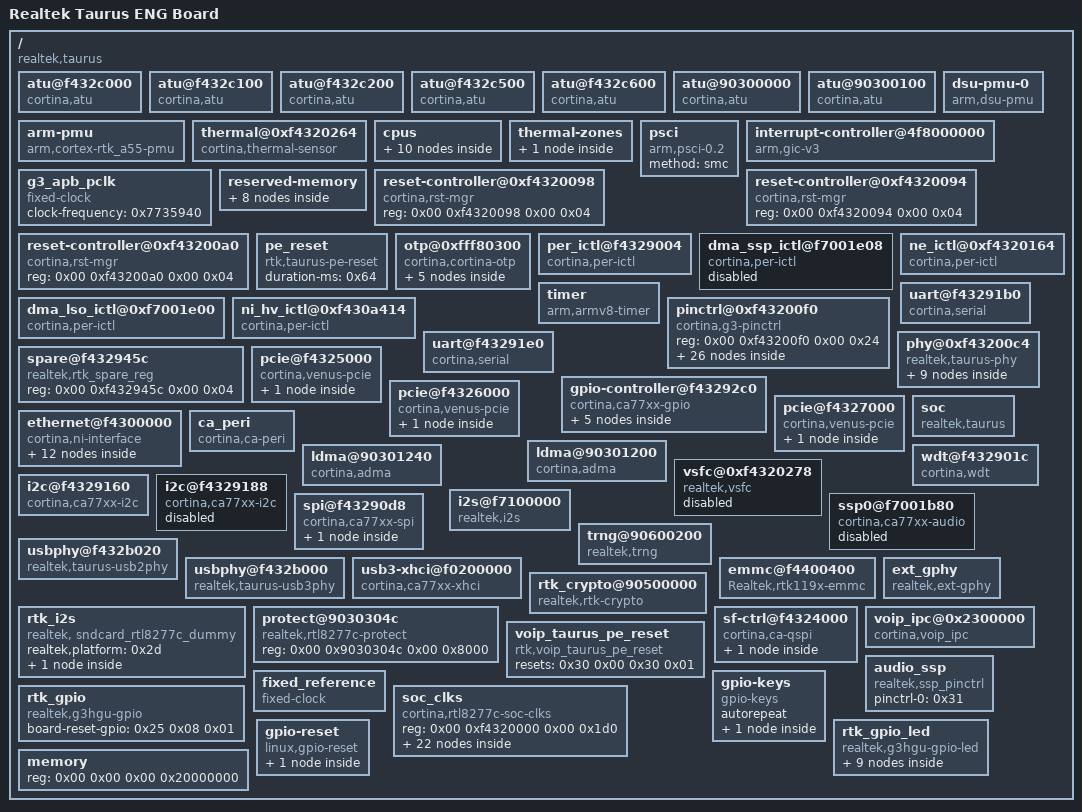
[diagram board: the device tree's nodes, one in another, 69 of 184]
/dts-v1/;

/ {
	model = "Realtek Taurus ENG Board";
	compatible = "realtek,taurus";
	#address-cells = <0x02>;
	#size-cells = <0x02>;
	interrupt-parent = <0x01>;

	atu@f432c000 {
		compatible = "cortina,atu";
		reg = <0x00 0xf432c000 0x00 0x1c>;
		reg-names = "pcie0_atu";
		atu-type = <0x00>;
		coherent-hi-addr = <0x04>;
		#iommu-cells = <0x00>;
		phandle = <0x0f>;
	};

	atu@f432c100 {
		compatible = "cortina,atu";
		reg = <0x00 0xf432c100 0x00 0x1c>;
		reg-names = "pcie1_atu";
		atu-type = <0x00>;
		coherent-hi-addr = <0x04>;
		#iommu-cells = <0x00>;
		phandle = <0x14>;
	};

	atu@f432c200 {
		compatible = "cortina,atu";
		reg = <0x00 0xf432c200 0x00 0x1c>;
		reg-names = "pcie2_atu";
		atu-type = <0x00>;
		coherent-hi-addr = <0x04>;
		#iommu-cells = <0x00>;
		phandle = <0x18>;
	};

	atu@f432c500 {
		compatible = "cortina,atu";
		reg = <0x00 0xf432c500 0x00 0x1c>;
		reg-names = "usb0_atu";
		atu-type = <0x00>;
		coherent-hi-addr = <0x02>;
		#iommu-cells = <0x00>;
	};

	atu@f432c600 {
		compatible = "cortina,atu";
		reg = <0x00 0xf432c600 0x00 0x1c>;
		reg-names = "usb1_atu";
		atu-type = <0x00>;
		coherent-hi-addr = <0x02>;
		#iommu-cells = <0x00>;
	};

	atu@90300000 {
		compatible = "cortina,atu";
		reg = <0x00 0x90300000 0x00 0x20>;
		reg-names = "pe0_atu";
		atu-type = <0x01>;
		#iommu-cells = <0x00>;
		keep-init;
	};

	atu@90300100 {
		compatible = "cortina,atu";
		reg = <0x00 0x90300100 0x00 0x20>;
		reg-names = "pe1_atu";
		atu-type = <0x01>;
		#iommu-cells = <0x00>;
		keep-init;
	};

	arm-pmu {
		compatible = "arm,cortex-rtk_a55-pmu";
		interrupt-parent = <0x01>;
		interrupts = <0x01 0x17 0x04>;
	};

	dsu-pmu-0 {
		compatible = "arm,dsu-pmu";
		interrupt-parent = <0x01>;
		interrupts = <0x00 0x6a 0x04>;
		cpus = <0x02 0x03 0x04 0x05>;
	};

	thermal@0xf4320264 {
		compatible = "cortina,thermal-sensor";
		reg = <0x00 0xf4320264 0x00 0x10>;
		status = "okay";
		tms-reg-a = <0x7f80000>;
		tms-reg-b = <0x374000>;
		#thermal-sensor-cells = <0x00>;
		phandle = <0x07>;
	};

	cpus {
		#address-cells = <0x02>;
		#size-cells = <0x00>;

		cpu@0 {
			compatible = "arm,cortex-a55\0arm,armv8";
			device_type = "cpu";
			reg = <0x00 0x00>;
			clocks = <0x06>;
			clock-names = "cpu";
			operating-points = <0x124f80 0xf4240 0x10c8e0 0xf4240 0xf4240 0xf4240 0xdbba0 0xf4240 0xc3500 0xf4240 0xaae60 0xf4240 0x98968 0xf4240 0x61a80 0xf4240>;
			enable-method = "psci";
			#cooling-cells = <0x02>;
			phandle = <0x02>;
		};

		cpu@100 {
			compatible = "arm,cortex-a55\0arm,armv8";
			device_type = "cpu";
			reg = <0x00 0x100>;
			clocks = <0x06>;
			clock-names = "cpu";
			operating-points = <0x124f80 0xf4240 0x10c8e0 0xf4240 0xf4240 0xf4240 0xdbba0 0xf4240 0xc3500 0xf4240 0xaae60 0xf4240 0x98968 0xf4240 0x61a80 0xf4240>;
			enable-method = "psci";
			#cooling-cells = <0x02>;
			phandle = <0x03>;
		};

		cpu@200 {
			compatible = "arm,cortex-a55\0arm,armv8";
			device_type = "cpu";
			reg = <0x00 0x200>;
			clocks = <0x06>;
			clock-names = "cpu";
			operating-points = <0x124f80 0xf4240 0x10c8e0 0xf4240 0xf4240 0xf4240 0xdbba0 0xf4240 0xc3500 0xf4240 0xaae60 0xf4240 0x98968 0xf4240 0x61a80 0xf4240>;
			enable-method = "psci";
			#cooling-cells = <0x02>;
			phandle = <0x04>;
		};

		cpu@300 {
			compatible = "arm,cortex-a55\0arm,armv8";
			device_type = "cpu";
			reg = <0x00 0x300>;
			clocks = <0x06>;
			clock-names = "cpu";
			operating-points = <0x124f80 0xf4240 0x10c8e0 0xf4240 0xf4240 0xf4240 0xdbba0 0xf4240 0xc3500 0xf4240 0xaae60 0xf4240 0x98968 0xf4240 0x61a80 0xf4240>;
			enable-method = "psci";
			#cooling-cells = <0x02>;
			phandle = <0x05>;
		};

		cpu-map {

			cluster0 {

				core0 {
					cpu = <0x02>;
				};

				core1 {
					cpu = <0x03>;
				};

				core2 {
					cpu = <0x04>;
				};

				core3 {
					cpu = <0x05>;
				};
			};
		};
	};

	thermal-zones {

		cpu-thermal {
			polling-delay-passive = <0x1f4>;
			polling-delay = <0xbb8>;
			thermal-sensors = <0x07>;
		};
	};

	psci {
		compatible = "arm,psci-0.2";
		method = "smc";
	};

	interrupt-controller@4f8000000 {
		compatible = "arm,gic-v3";
		#interrupt-cells = <0x03>;
		interrupt-controller;
		#redistributor-regions = <0x01>;
		reg = <0x04 0xf8000000 0x00 0x10000 0x04 0xf8040000 0x00 0x80000>;
		interrupts = <0x01 0x09 0x04>;
		phandle = <0x01>;
	};

	g3_apb_pclk {
		compatible = "fixed-clock";
		#clock-cells = <0x00>;
		clock-frequency = <0x7735940>;
		phandle = <0x09>;
	};

	reserved-memory {
		#address-cells = <0x02>;
		#size-cells = <0x02>;
		ranges;

		ddr_cache_buffer@0x0bc48000 {
			reg = <0x00 0xbc48000 0x00 0x60000>;
			phandle = <0x21>;
		};

		ddr_noncache_buffer@0x09000000 {
			reg = <0x00 0x9000000 0x00 0x1a50000>;
			phandle = <0x22>;
		};

		tz_buffer@FFE0000 {
			reg = <0x00 0xffe0000 0x00 0x20000>;
		};

		tz_smc_buf@0xFFDF000 {
			reg = <0x00 0xffdf000 0x00 0x1000>;
			no-map;
		};

		pstore_buf@0xEF00000 {
			no-map;
			reg = <0x00 0xef00000 0x00 0x100000>;
		};

		voip_vector_buffer@0x0 {
			reg = <0x00 0x00 0x00 0x1000>;
			no-map;
		};

		voip_buffer@0x2000000 {
			reg = <0x00 0x2000000 0x00 0x300000>;
			no-map;
			phandle = <0x2f>;
		};

		voip_ipc_noncache_buffer@0x2300000 {
			reg = <0x00 0x2300000 0x00 0x100000>;
			no-map;
			phandle = <0x2e>;
		};
	};

	reset-controller@0xf4320098 {
		compatible = "cortina,rst-mgr";
		reg = <0x00 0xf4320098 0x00 0x04>;
		#reset-cells = <0x01>;
		phandle = <0x1e>;
	};

	reset-controller@0xf4320094 {
		compatible = "cortina,rst-mgr";
		reg = <0x00 0xf4320094 0x00 0x04>;
		#reset-cells = <0x01>;
		phandle = <0x20>;
	};

	reset-controller@0xf43200a0 {
		compatible = "cortina,rst-mgr";
		reg = <0x00 0xf43200a0 0x00 0x04>;
		#reset-cells = <0x01>;
		phandle = <0x1f>;
	};

	pe_reset {
		compatible = "rtk,taurus-pe-reset";
		duration-ms = <0x64>;
		#reset-cells = <0x01>;
		phandle = <0x30>;
	};

	otp@0xfff80300 {
		compatible = "cortina,cortina-otp";
		#address-cells = <0x01>;
		#size-cells = <0x01>;
		reg = <0x00 0xfff80300 0x00 0x100>;
		ngroups = <0x100>;
		redundant;

		uuid@0x74 {
			reg = <0x74 0x04>;
		};

		hvsid@0x78 {
			reg = <0x78 0x04>;
		};

		param@0x80 {
			reg = <0x80 0x04>;
			phandle = <0x1b>;
		};

		patch@0x84 {
			reg = <0x84 0x10>;
			phandle = <0x1d>;
		};

		calib@0x94 {
			reg = <0x94 0x20>;
			phandle = <0x1c>;
		};
	};

	per_ictl@f4329004 {
		compatible = "cortina,per-ictl";
		reg = <0x00 0xf4329004 0x00 0x10>;
		interrupt-controller;
		#interrupt-cells = <0x01>;
		interrupt-parent = <0x01>;
		interrupts = <0x00 0x02 0x04>;
		phandle = <0x0a>;
	};

	dma_ssp_ictl@f7001e08 {
		compatible = "cortina,per-ictl";
		reg = <0x00 0xf7001e08 0x00 0x08>;
		interrupt-controller;
		#interrupt-cells = <0x01>;
		interrupt-parent = <0x01>;
		interrupts = <0x00 0x10 0x04>;
		status = "disabled";
		phandle = <0x28>;
	};

	dma_lso_ictl@0xf7001e00 {
		compatible = "cortina,per-ictl";
		reg = <0x00 0xf7001e00 0x00 0x08>;
		interrupt-controller;
		#interrupt-cells = <0x01>;
		interrupt-parent = <0x01>;
		interrupts = <0x00 0x08 0x04>;
		phandle = <0x23>;
	};

	ne_ictl@0xf4320164 {
		compatible = "cortina,per-ictl";
		reg = <0x00 0xf4320164 0x00 0x10>;
		interrupt-controller;
		#interrupt-cells = <0x01>;
		interrupt-parent = <0x01>;
		interrupts = <0x00 0x01 0x04>;
		phandle = <0x08>;
	};

	ni_hv_ictl@0xf430a414 {
		compatible = "cortina,per-ictl";
		reg = <0x00 0xf430a414 0x00 0x08>;
		interrupt-controller;
		#interrupt-cells = <0x01>;
		interrupt-parent = <0x08>;
		interrupts = <0x00>;
		phandle = <0x24>;
	};

	timer {
		compatible = "arm,armv8-timer";
		interrupt-parent = <0x01>;
		interrupts = <0x01 0x0d 0xff08 0x01 0x0e 0xff08 0x01 0x0b 0xff08 0x01 0x0a 0xff08>;
		clock-frequency = <0x17d7840>;
	};

	pinctrl@0xf43200f0 {
		compatible = "cortina,g3-pinctrl";
		reg = <0x00 0xf43200f0 0x00 0x24>;
		phandle = <0x0b>;

		uart0_active {

			data_signals {
				pins = "PMUX_003";
				function = "multi-fn";
			};
		};

		uart2_active {

			data_signals {
				pins = "GPIO_000\0GPIO_001\0PMUX_004";
				function = "multi-fn";
			};
		};

		uart3_active {

			data_signals {
				pins = "GPIO_002\0GPIO_003\0PMUX_005";
				function = "multi-fn";
			};
		};

		spi_cs1 {

			data_signals {
				pins = "GPIO_004\0PMUX_006";
				function = "multi-fn";
			};
		};

		spi_cs2 {

			data_signals {
				pins = "GPIO_005\0PMUX_007";
				function = "multi-fn";
			};
		};

		spi_cs3 {

			data_signals {
				pins = "GPIO_006\0PMUX_008";
				function = "multi-fn";
			};
		};

		spi_cs4 {

			data_signals {
				pins = "GPIO_007\0PMUX_009";
				function = "multi-fn";
			};
		};

		led_ctrl_active {

			data_signals {
				pins = "GPIO_011\0GPIO_012\0PMUX_019";
				function = "multi-fn";
			};
		};

		mdio_default {

			data_signals {
				pins = "GPIO_402\0GPIO_403\0PMUX_111";
				function = "multi-fn";
			};
		};

		i2c0_default {
			phandle = <0x26>;

			data_signals {
				pins = "GPIO_204\0GPIO_205\0PMUX_120";
				function = "multi-fn";
			};
		};

		rgmii_default {

			data_signals {
				pins = "GPIO_313\0GPIO_314\0GPIO_315\0GPIO_316\0GPIO_317\0GPIO_318\0GPIO_319\0GPIO_320\0GPIO_321\0GPIO_322\0GPIO_323\0GPIO_324\0PMUX_114";
				function = "multi-fn";
			};
		};

		voip_spi {
			phandle = <0x27>;

			data_signals {
				pins = "GPIO_200\0GPIO_201\0GPIO_202\0GPIO_203\0PMUX_106";
				function = "multi-fn";
			};
		};

		ssp {
			phandle = <0x31>;

			data_signals {
				pins = "GPIO_206\0GPIO_207\0GPIO_208\0GPIO_209\0GPIO_210\0GPIO_211\0PMUX_104";
				function = "multi-fn";
			};
		};
	};

	uart@f43291b0 {
		device_type = "serial";
		compatible = "cortina,serial";
		reg = <0x00 0xf43291b0 0x00 0x30>;
		clocks = <0x09>;
		interrupts = <0x00 0x04 0x04>;
		wakeup-source;
	};

	uart@f43291e0 {
		device_type = "serial";
		compatible = "cortina,serial";
		reg = <0x00 0xf43291e0 0x00 0x30>;
		clocks = <0x09>;
		interrupts = <0x00 0x05 0x04>;
	};

	spare@f432945c {
		compatible = "realtek,rtk_spare_reg";
		reg = <0x00 0xf432945c 0x00 0x04>;
	};

	gpio-controller@f43292c0 {
		#address-cells = <0x01>;
		#size-cells = <0x00>;
		compatible = "cortina,ca77xx-gpio";
		reg = <0x00 0xf43292c0 0x00 0xb4 0x00 0xf4320100 0x00 0x14>;
		id = <0x00>;

		bank@0 {
			gpio-controller;
			interrupt-controller;
			reg = <0x00>;
			ngpios = <0x10>;
			#gpio-cells = <0x02>;
			#interrupt-cells = <0x02>;
			interrupt-parent = <0x0a>;
			interrupts = <0x08>;
			gpio-ranges = <0x0b 0x00 0x00 0x20>;
			phandle = <0x25>;
		};

		bank@1 {
			gpio-controller;
			interrupt-controller;
			reg = <0x01>;
			ngpios = <0x11>;
			#gpio-cells = <0x02>;
			#interrupt-cells = <0x02>;
			interrupt-parent = <0x0a>;
			interrupts = <0x09>;
			gpio-ranges = <0x0b 0x00 0x20 0x20>;
		};

		bank@2 {
			gpio-controller;
			interrupt-controller;
			reg = <0x02>;
			ngpios = <0x0c>;
			#gpio-cells = <0x02>;
			#interrupt-cells = <0x02>;
			interrupt-parent = <0x0a>;
			interrupts = <0x0a>;
			gpio-ranges = <0x0b 0x00 0x40 0x20>;
		};

		bank@3 {
			gpio-controller;
			interrupt-controller;
			reg = <0x03>;
			ngpios = <0x19>;
			#gpio-cells = <0x02>;
			#interrupt-cells = <0x02>;
			interrupt-parent = <0x0a>;
			interrupts = <0x0b>;
			gpio-ranges = <0x0b 0x00 0x60 0x20>;
		};

		bank@4 {
			gpio-controller;
			interrupt-controller;
			reg = <0x04>;
			ngpios = <0x11>;
			#gpio-cells = <0x02>;
			#interrupt-cells = <0x02>;
			interrupt-parent = <0x0a>;
			interrupts = <0x0c>;
			gpio-ranges = <0x0b 0x00 0x80 0x20>;
			phandle = <0x3d>;
		};
	};

	phy@0xf43200c4 {
		#address-cells = <0x01>;
		#size-cells = <0x00>;
		compatible = "realtek,taurus-phy";
		reg = <0x00 0xf43200c4 0x00 0x20 0x00 0xf432036c 0x00 0x04>;
		reg-names = "control\0power";

		phy@0 {
			reg = <0x00>;
			#phy-cells = <0x00>;
			phandle = <0x0c>;
		};

		phy@1 {
			reg = <0x01>;
			#phy-cells = <0x00>;
			phandle = <0x0d>;
		};

		phy@9 {
			reg = <0x09>;
			#phy-cells = <0x00>;
		};

		phy@2 {
			reg = <0x02>;
			#phy-cells = <0x00>;
			phandle = <0x11>;
		};

		phy@3 {
			reg = <0x03>;
			#phy-cells = <0x00>;
			phandle = <0x12>;
		};

		phy@4 {
			reg = <0x04>;
			#phy-cells = <0x00>;
			phandle = <0x16>;
		};

		phy@5 {
			reg = <0x05>;
			#phy-cells = <0x00>;
			phandle = <0x29>;
		};

		phy@6 {
			reg = <0x06>;
			#phy-cells = <0x00>;
			phandle = <0x2a>;
		};

		phy@7 {
			reg = <0x07>;
			#phy-cells = <0x00>;
			serdes-reg = <0x00 0xf4600000 0x00 0x1000>;
			phandle = <0x1a>;
		};
	};

	pcie@f4325000 {
		compatible = "cortina,venus-pcie";
		reg = <0x00 0xf4325000 0x00 0x400 0x00 0xa0000000 0x00 0x1000 0x00 0xa0001000 0x00 0x2000 0x00 0xa0300000 0x00 0x100000 0x00 0xf4333000 0x00 0x2000>;
		reg-names = "glbl_regs\0rc_dbi\0config\0iatu\0serdes_phy";
		phys = <0x0c 0x0d>;
		phy-names = "pcie-phy0\0pcie-phy1";
		#address-cells = <0x03>;
		#size-cells = <0x02>;
		device_type = "pci";
		bus-range = <0x00 0xff>;
		ranges = <0x81000000 0x00 0x00 0x00 0xa0003000 0x00 0x10000 0x82000000 0x00 0xa0400000 0x00 0xa0400000 0x00 0xfc00000>;
		id = <0x00>;
		num-viewport = <0x01>;
		num-lanes = <0x01>;
		clocks = <0x0e>;
		iommus = <0x0f>;
		interrupt-parent = <0x01>;
		interrupts = <0x00 0x2a 0x04 0x00 0x2b 0x04 0x00 0x2c 0x04 0x00 0x2d 0x04>;
		irq-affinity = <0x01>;
		serdes-cfg-verA = "revA v1.3 (2022.04.22)";
		serdes-cfg-verB = "revB v1.2 (2022.04.22)";
		serdes-cfg-dataA = <0x04 0xa855 0x18 0x0a 0x20 0x3591 0x28 0x8670 0x2c 0xb90d 0x34 0xf71a 0x38 0x1000 0x74 0xda1f 0x80 0xd477 0x88 0x23 0x8c 0xb66 0x90 0x4f30 0xa0 0xf802 0xc0 0x55 0x24 0x500c 0x24 0x520c 0x104 0xa84a 0x118 0x0a 0x120 0x3591 0x128 0x8650 0x12c 0xb90d 0x134 0xf71a 0x138 0x1000 0x174 0xda1f 0x180 0xd477 0x184 0x55aa 0x188 0x23 0x18c 0xb66 0x1a0 0xf802 0x1bc 0x3900 0x1c0 0x4a 0x124 0x500c 0x124 0x520c>;
		serdes-cfg-dataB = <0x04 0xa855 0x08 0x60c6 0x18 0x1f 0x20 0x3591 0x28 0xf670 0x2c 0xa90d 0x34 0xf71a 0x38 0x1000 0x74 0xda1f 0x80 0xd477 0x88 0x23 0x8c 0xb66 0x90 0x4f30 0xa0 0xf802 0xc0 0x55 0xc8 0xf0f3 0x24 0x500c 0x24 0x520c 0x104 0xa84a 0x108 0x60c6 0x118 0x1f 0x120 0x3591 0x128 0xf670 0x12c 0xa90d 0x134 0xf71a 0x138 0x1000 0x174 0xda1f 0x180 0xd479 0x184 0x55aa 0x188 0x23 0x18c 0xb66 0x190 0x4f0c 0x1a0 0xf802 0x1bc 0x3900 0x1c0 0x4a 0x1c8 0xf0f3 0x124 0x500c 0x124 0x520c>;
		#interrupt-cells = <0x01>;
		interrupt-map-mask = <0x00 0x00 0x00 0x07>;
		interrupt-map = <0x00 0x00 0x00 0x01 0x10 0x00 0x00 0x00 0x00 0x02 0x10 0x01 0x00 0x00 0x00 0x03 0x10 0x02 0x00 0x00 0x00 0x04 0x10 0x03>;

		interrupt-controller {
			interrupt-controller;
			#address-cells = <0x00>;
			#interrupt-cells = <0x01>;
			phandle = <0x10>;
		};
	};

	pcie@f4326000 {
		compatible = "cortina,venus-pcie";
		reg = <0x00 0xf4326000 0x00 0x400 0x00 0xb0000000 0x00 0x1000 0x00 0xb0001000 0x00 0x2000 0x00 0xb0300000 0x00 0x100000 0x00 0xf4335000 0x00 0x2000>;
		reg-names = "glbl_regs\0rc_dbi\0config\0iatu\0serdes_phy";
		phys = <0x11 0x12>;
		phy-names = "pcie-phy0\0pcie-phy1";
		#address-cells = <0x03>;
		#size-cells = <0x02>;
		device_type = "pci";
		bus-range = <0x00 0xff>;
		ranges = <0x81000000 0x00 0x00 0x00 0xb0003000 0x00 0x10000 0x82000000 0x00 0xb0400000 0x00 0xb0400000 0x00 0xfc00000>;
		id = <0x01>;
		num-viewport = <0x01>;
		num-lanes = <0x01>;
		clocks = <0x13>;
		iommus = <0x14>;
		interrupt-parent = <0x01>;
		interrupts = <0x00 0x2e 0x04 0x00 0x2f 0x04 0x00 0x30 0x04 0x00 0x31 0x04>;
		irq-affinity = <0x01>;
		serdes-cfg-verA = "revA v1.3 (2022.04.22)";
		serdes-cfg-verB = "revB v1.2 (2022.04.22)";
		serdes-cfg-dataA = <0x04 0xa855 0x18 0x0a 0x20 0x3591 0x28 0x8670 0x2c 0xb90d 0x34 0xf71a 0x38 0x1000 0x74 0xda1f 0x80 0xd477 0x88 0x23 0x8c 0xb66 0x90 0x4f30 0xa0 0xf802 0xc0 0x55 0x24 0x500c 0x24 0x520c 0x104 0xa84a 0x118 0x0a 0x120 0x3591 0x128 0x8650 0x12c 0xb90d 0x134 0xf71a 0x138 0x1000 0x174 0xda1f 0x180 0xd477 0x184 0x55aa 0x188 0x23 0x18c 0xb66 0x1a0 0xf802 0x1bc 0x3900 0x1c0 0x4a 0x124 0x500c 0x124 0x520c>;
		serdes-cfg-dataB = <0x04 0xa855 0x08 0x60c6 0x18 0x1f 0x20 0x3591 0x28 0xf670 0x2c 0xa90d 0x34 0xf71a 0x38 0x1000 0x74 0xda1f 0x80 0xd477 0x88 0x23 0x8c 0xb66 0x90 0x4f30 0xa0 0xf802 0xc0 0x55 0xc8 0xf0f3 0x24 0x500c 0x24 0x520c 0x104 0xa84a 0x108 0x60c6 0x118 0x1f 0x120 0x3591 0x128 0xf670 0x12c 0xa90d 0x134 0xf71a 0x138 0x1000 0x174 0xda1f 0x180 0xd479 0x184 0x55aa 0x188 0x23 0x18c 0xb66 0x190 0x4f0c 0x1a0 0xf802 0x1bc 0x3900 0x1c0 0x4a 0x1c8 0xf0f3 0x124 0x500c 0x124 0x520c>;
		#interrupt-cells = <0x01>;
		interrupt-map-mask = <0x00 0x00 0x00 0x07>;
		interrupt-map = <0x00 0x00 0x00 0x01 0x15 0x00 0x00 0x00 0x00 0x02 0x15 0x01 0x00 0x00 0x00 0x03 0x15 0x02 0x00 0x00 0x00 0x04 0x15 0x03>;

		interrupt-controller {
			interrupt-controller;
			#address-cells = <0x00>;
			#interrupt-cells = <0x01>;
			phandle = <0x15>;
		};
	};

	pcie@f4327000 {
		compatible = "cortina,venus-pcie";
		reg = <0x00 0xf4327000 0x00 0x400 0x00 0xc0000000 0x00 0x1000 0x00 0xc0001000 0x00 0x2000 0x00 0xc0300000 0x00 0x100000 0x00 0xf4337000 0x00 0x1000>;
		reg-names = "glbl_regs\0rc_dbi\0config\0iatu\0serdes_phy";
		phys = <0x16>;
		phy-names = "pcie-phy0";
		#address-cells = <0x03>;
		#size-cells = <0x02>;
		device_type = "pci";
		bus-range = <0x00 0xff>;
		ranges = <0x81000000 0x00 0x00 0x00 0xc0003000 0x00 0x10000 0x82000000 0x00 0xc0400000 0x00 0xc0400000 0x00 0xfc00000>;
		id = <0x02>;
		num-viewport = <0x01>;
		num-lanes = <0x01>;
		clocks = <0x17>;
		iommus = <0x18>;
		interrupt-parent = <0x01>;
		interrupts = <0x00 0x32 0x04 0x00 0x33 0x04 0x00 0x34 0x04 0x00 0x35 0x04>;
		serdes-cfg-verA = "revA v1.3 (2022.04.22)";
		serdes-cfg-verB = "revB v1.2 (2022.04.22)";
		serdes-cfg-dataA = <0x04 0xa855 0x18 0x0a 0x20 0x3591 0x28 0x8670 0x2c 0xb90d 0x34 0xf71a 0x38 0x1000 0x70 0x2000 0x74 0xda1f 0x78 0x66eb 0x80 0xd477 0x88 0x23 0x8c 0xb66 0x90 0x4f30 0xa0 0xf802 0xbc 0x7055 0x24 0x500c 0x24 0x520c 0x104 0xa84a 0x118 0x0a 0x120 0x3591 0x128 0x8650 0x12c 0xb90d 0x134 0xf71a 0x138 0x1000 0x170 0x2000 0x174 0xda1f 0x180 0xd477 0x184 0x55aa 0x188 0x23 0x18c 0xb66 0x1a0 0xf802 0x1bc 0x704a 0x124 0x500c 0x124 0x520c>;
		serdes-cfg-dataB = <0x04 0xa855 0x08 0x60c6 0x18 0x1f 0x20 0x3591 0x28 0xf670 0x2c 0xa90d 0x34 0xf71a 0x38 0x1000 0x70 0x2000 0x74 0xda1f 0x78 0x66eb 0x80 0xd477 0x88 0x23 0x8c 0xb66 0x90 0x4f30 0xa0 0xf802 0xbc 0x7055 0xc8 0xf0f3 0x24 0x500c 0x24 0x520c 0x104 0xa84a 0x108 0x60c6 0x118 0x1f 0x120 0x3591 0x128 0xf670 0x12c 0xa90d 0x134 0xf71a 0x138 0x1000 0x170 0x2000 0x174 0xda1f 0x180 0xd479 0x184 0x55aa 0x188 0x23 0x18c 0xb66 0x190 0x4f0c 0x1a0 0xf802 0x1bc 0x704a 0x1c8 0xf0f3 0x124 0x500c 0x124 0x520c>;
		#interrupt-cells = <0x01>;
		interrupt-map-mask = <0x00 0x00 0x00 0x07>;
		interrupt-map = <0x00 0x00 0x00 0x01 0x19 0x00 0x00 0x00 0x00 0x02 0x19 0x01 0x00 0x00 0x00 0x03 0x19 0x02 0x00 0x00 0x00 0x04 0x19 0x03>;

		interrupt-controller {
			interrupt-controller;
			#address-cells = <0x00>;
			#interrupt-cells = <0x01>;
			phandle = <0x19>;
		};
	};

	soc {
		compatible = "realtek,taurus";
		reg = <0x00 0xf4320000 0x00 0x04 0x00 0xf4320200 0x00 0x44 0x00 0xf43200ac 0x00 0x04>;
		reg-names = "JTAG_ID\0CLOCK\0STRAP";
	};

	ethernet@f4300000 {
		compatible = "cortina,ni-interface";
		reg = <0x04 0xf4300000 0x00 0x10000 0x04 0xf4320164 0x00 0x10 0x04 0xf4329118 0x00 0x48 0x00 0xf4500000 0x00 0x2000 0x04 0xf7001000 0x00 0x1000 0x00 0x80000000 0x00 0x3c000 0x00 0xbc48000 0x00 0x60000 0x01 0x9000000 0x00 0x1a50000 0x04 0xf5500000 0x00 0xc000 0x04 0xf4320000 0x00 0x300 0x04 0xf432d000 0x00 0x20b8 0x04 0xf4600000 0x00 0x100000 0x04 0xf550c000 0x00 0x1000 0x04 0xf433a000 0x00 0x1000 0x04 0xf550d000 0x00 0x1000 0x04 0xf4700000 0x00 0x100 0x00 0x90301000 0x00 0x2000 0x04 0xf4333000 0x00 0x6000>;
		interrupt-parent = <0x01>;
		interrupts = <0x00 0x54 0x04 0x00 0x55 0x04 0x00 0x56 0x04 0x00 0x57 0x04 0x00 0x58 0x04 0x00 0x59 0x04 0x00 0x5a 0x04 0x00 0x5b 0x04 0x00 0x4b 0x04 0x00 0x4c 0x04 0x00 0x4d 0x04 0x00 0x4e 0x04 0x00 0x47 0x04 0x00 0x48 0x04 0x00 0x49 0x04 0x00 0x4a 0x04>;
		phys = <0x1a>;
		phy-names = "sgmii-phy";
		nvmem-cells = <0x1b 0x1c 0x1d>;
		nvmem-cell-names = "param\0calibration\0phy_patch";
		resets = <0x1e 0x00 0x1e 0x01 0x1e 0x02 0x1e 0x03 0x1e 0x04 0x1e 0x05 0x1f 0x07 0x1f 0x08 0x1e 0x1e 0x20 0x03>;
		reset-names = "ni_reset\0l2fe_reset\0l2tm_reset\0l3fe_reset\0sdram_reset\0tqm_reset\0phy_sdsif_reset\0phy_sgmii_reset\0ptp_timer_reset\0ptp_reset";
		memory-region = <0x21 0x22>;

		ethernet@0 {
			local-mac-address = [00 00 00 00 00 00];
		};

		ethernet@1 {
			local-mac-address = [00 00 00 00 00 00];
		};

		pon_ictl@0 {
			interrupt-parent = <0x08>;
			interrupts = <0x05>;
		};

		dma_lso_vp10_int@10 {
			interrupt-parent = <0x23>;
			interrupts = <0x0a>;
			interrupt-names = "DMA_LSO_VP10_INT";
		};

		dma_lso_vp11_int@11 {
			interrupt-parent = <0x23>;
			interrupts = <0x0b>;
			interrupt-names = "DMA_LSO_VP11_INT";
		};

		dma_lso_int@12 {
			interrupt-parent = <0x23>;
			interrupts = <0x0c>;
			interrupt-names = "DMA_LSO_INT";
		};

		dg_int@24 {
			interrupt-parent = <0x0a>;
			interrupts = <0x18>;
			interrupt-names = "DG_INT";
		};

		ni_ptp_ictl@0xf430439c {
			compatible = "cortina,per-ictl";
			interrupt-controller;
			#interrupt-cells = <0x01>;
			interrupt-parent = <0x08>;
			interrupts = <0x05>;
		};

		ni_gphy_ictl@0 {
			interrupt-parent = <0x01>;
			interrupts = <0x00 0x3d 0x04 0x00 0x3e 0x04 0x00 0x3f 0x04 0x00 0x40 0x04>;
		};

		ni_sfi_int@0 {
			interrupt-parent = <0x24>;
			interrupts = <0x16>;
			interrupt-names = "SFI ITNT";
		};

		ni_sfi_los_int@0 {
			interrupt-parent = <0x25>;
			interrupts = <0x02 0x03>;
			interrupt-names = "SFI LOS ITNT";
		};

		dying_gasp@0 {
			interrupt-parent = <0x0a>;
			interrupts = <0x18>;
			interrupt-names = "DYING GASP";
		};
	};

	ca_peri {
		compatible = "cortina,ca-peri";
		reg = <0x00 0xf4329018 0x00 0x460 0x00 0xf4320000 0x00 0x60>;
		interrupt-parent = <0x0a>;
		interrupts = <0x02>;
		interrupt-names = "TMR1";
	};

	ldma@90301200 {
		compatible = "cortina,adma";
		reg = <0x00 0x90301200 0x00 0x40 0x00 0x90301600 0x00 0x40 0x00 0x90301000 0x00 0x60 0x00 0x903011a0 0x00 0x10>;
		dma-coherent;
		ldma-channel-id = <0x00>;
		ldma-irq-mux = <0x00>;
		interrupts = <0x00 0x21 0x04>;
	};

	ldma@90301240 {
		compatible = "cortina,adma";
		reg = <0x00 0x90301240 0x00 0x40 0x00 0x90301600 0x00 0x40 0x00 0x90301000 0x00 0x60 0x00 0x903011a0 0x00 0x10>;
		dma-coherent;
		ldma-channel-id = <0x01>;
		ldma-irq-mux = <0x01>;
		interrupts = <0x00 0x22 0x04>;
	};

	wdt@f432901c {
		compatible = "cortina,wdt";
		reg = <0x00 0xf432901c 0x00 0x30 0x00 0xf43200c0 0x00 0x04>;
		interrupt-parent = <0x0a>;
		interrupts = <0x06>;
		clocks = <0x09>;
		reset-on-timeout;
		delay-reset = <0x86>;
	};

	vsfc@0xf4320278 {
		compatible = "realtek,vsfc";
		reg = <0x00 0xf4320278 0x00 0x4c>;
		trig_sel = <0x01>;
		div_sel = <0x00>;
		core_idle_div_en = <0x01>;
		core_min = <0x04>;
		det_recv_sel = <0x01>;
		recv_ctrl1 = <0xaaaa0080>;
		recv_ctrl2 = <0x88880100>;
		recv_ctrl3 = <0x8080140>;
		status = "disabled";
	};

	i2c@f4329160 {
		#address-cells = <0x01>;
		#size-cells = <0x00>;
		compatible = "cortina,ca77xx-i2c";
		reg = <0x00 0xf4329160 0x00 0x28>;
		interrupt-parent = <0x0a>;
		interrupts = <0x0d>;
		device_type = "i2c";
		clocks = <0x09>;
		pinctrl-0 = <0x26>;
		pinctrl-names = "default";
		clock-frequency = <0x186a0>;
		timeout = <0x3e8>;
		retries = <0x03>;
	};

	i2c@f4329188 {
		#address-cells = <0x01>;
		#size-cells = <0x00>;
		compatible = "cortina,ca77xx-i2c";
		reg = <0x00 0xf4329188 0x00 0x28>;
		interrupt-parent = <0x0a>;
		interrupts = <0x1a>;
		device_type = "i2c";
		clocks = <0x09>;
		status = "disabled";
		clock-frequency = <0x186a0>;
		timeout = <0x3e8>;
		retries = <0x03>;
	};

	i2s@f7100000 {
		compatible = "realtek,i2s";
		reg = <0x00 0xf7100000 0x00 0x44 0x00 0xf4320000 0x00 0x200 0x00 0xf550a000 0x00 0x64>;
		reg-names = "i2s_reg\0glb_reg\0psds_reg";
		interrupt-parent = <0x01>;
		interrupts = <0x00 0x20 0x04>;
	};

	spi@f43290d8 {
		compatible = "cortina,ca77xx-spi";
		reg = <0x00 0xf43290d8 0x00 0x40>;
		interrupt-parent = <0x0a>;
		interrupts = <0x07>;
		clocks = <0x09>;
		#address-cells = <0x01>;
		#size-cells = <0x00>;

		slic_spi0@0 {
			compatible = "realtek,support-slic";
			status = "okay";
			spi-max-frequency = <0x2625a0>;
			reg = <0x00>;
			reset-gpio = <0x25 0x03 0x01>;
			pinctrl-0 = <0x27>;
			pinctrl-names = "default";
		};
	};

	ssp0@f7001b80 {
		compatible = "cortina,ca77xx-audio";
		reg = <0x00 0xf7001b80 0x00 0x80 0x00 0xf7001064 0x00 0x08 0x00 0xf7001a80 0x00 0x80>;
		reg-names = "ssp\0dma-glb\0dma-ssp";
		interrupt-parent = <0x28>;
		interrupts = <0x06 0x02 0x03>;
		interrupt-names = "ssp\0dma-tx\0dma-rx";
		status = "disabled";
	};

	trng@90600200 {
		compatible = "realtek,trng";
		reg = <0x00 0x90600200 0x00 0x68>;
		interrupt-parent = <0x01>;
		interrupts = <0x00 0x3b 0x04>;
		self-test;
	};

	usbphy@f432b020 {
		compatible = "realtek,taurus-usb2phy";
		reg = <0x00 0xf432b020 0x00 0x18>;
		reg-names = "u2host_reg";
		#address-cells = <0x02>;
		#size-cells = <0x02>;
		ranges;
		resets = <0x1e 0x0d>;
		reset-names = "usbcore_reset";
		portmask = <0x03>;
		phy_data_verA = "revA v1.1 (2021.12.13)";
		phy_data_addrA = [e0 e2 e4 e7 f4 e7 f4 e0 e0 e0];
		phy_data_arrayA = [1f f9 68 71 db 44 bb 25 21 25];
		phy_data_verB = "revB v1.2 (2022.09.13)";
		phy_data_addrB = [e0 e2 e4 e7 f4 e7 f4 e0 e0 e0];
		phy_data_arrayB = [1f f9 6b 71 db 83 bb 26 22 26];
		phandle = <0x2b>;
	};

	usbphy@f432b000 {
		compatible = "realtek,taurus-usb3phy";
		reg = <0x00 0xf432b000 0x00 0x20 0x00 0xf432b04c 0x00 0x10 0x00 0xf4337000 0x00 0x1000 0x00 0xf4338000 0x00 0x1000>;
		reg-names = "u3host_reg\0u3ext_reg\0s2usbphy_u3port\0s3usbphy_u3port";
		#address-cells = <0x02>;
		#size-cells = <0x02>;
		ranges;
		phys = <0x29 0x2a>;
		phy-names = "s2usb3-phy\0s3usb3-phy";
		phymask = <0x01>;
		phy_data_verA = "revA v1.1 (2021.10.28)";
		phy_data_addrA = <0x1040508 0x90a0b0d 0xe202122 0x23272b33>;
		phy_data_arrayA = <0xaccc7000 0x631330d1 0x424ca610 0xb905ef2e 0x1000705e 0xf8e80003 0xb660241 0x380001>;
		phy_data_verB = "revB v1.0 (2022.02.24)";
		phy_data_addrB = [01 04 05 08 09 0a 0b 0d 0e 20 21 22 23 27 2b 33 09 09 09];
		phy_data_arrayB = [ac cc 70 00 63 13 30 d1 42 4c c6 10 a9 05 ef 2e 10 00 70 5e f8 e8 00 03 0b 66 02 41 00 38 00 01 42 4c 40 4c 42 4c];
		usb2-phy = <0x2b>;
		phandle = <0x2c>;
	};

	usb3-xhci@f0200000 {
		compatible = "cortina,ca77xx-xhci";
		#address-cells = <0x02>;
		#size-cells = <0x02>;
		reg = <0x00 0xf0200000 0x00 0x80000>;
		reg-names = "usb3-xhci-reg";
		ranges;
		interrupt-parent = <0x01>;
		interrupts = <0x00 0x42 0x04>;
		usb-phy = <0x2c>;
	};

	emmc@f4400400 {
		compatible = "Realtek,rtk119x-emmc";
		reg = <0x00 0xf4400400 0x00 0x1b1 0x00 0xf4320350 0x00 0x18 0x00 0xf432009c 0x00 0x04>;
		interrupt-parent = <0x01>;
		interrupts = <0x00 0x29 0x04>;
		resets = <0x1e 0x1c>;
		reset-names = "sd_reset";
		no-sd;
		no-sdio;
		bus-width = <0x08>;
		max-frequency = <0xbebc200>;
		non-removable;
		cap-mmc-highspeed;
		cap-mmc-hw-reset;
		mmc-ddr-3_3v;
		mmc-ddr-1_8v;
		mmc-hs200-1_8v;
	};

	ext_gphy {
		compatible = "realtek,ext-gphy";
		num-cells = <0x02>;
		port_mapping_phyAddr = <0x04 0x07 0x06 0x08>;
	};

	rtk_i2s {
		compatible = "realtek, sndcard_rtl8277c_dummy";
		status = "okay";
		realtek,platform = <0x2d>;

		test@0 {
			compatible = "realtek,platform";
			phandle = <0x2d>;
		};
	};

	protect@9030304c {
		compatible = "realtek,rtl8277c-protect";
		#address-cells = <0x01>;
		#size-cells = <0x01>;
		reg = <0x00 0x9030304c 0x00 0x8000>;
		ranges = <0x00 0x00 0x9030304c 0x100000>;
	};

	rtk_crypto@90500000 {
		compatible = "realtek,rtk-crypto";
		#address-cells = <0x01>;
		#size-cells = <0x01>;
		reg = <0x00 0x90500000 0x00 0x8000>;
		ranges = <0x00 0x00 0x90500000 0x100000>;
		revision = <0x20200104>;
		interrupt-parent = <0x01>;
		interrupts = <0x00 0x39 0x04>;
	};

	sf-ctrl@f4324000 {
		compatible = "cortina,ca-qspi";
		#address-cells = <0x02>;
		#size-cells = <0x02>;
		reg = <0x04 0xf4324000 0x00 0x50>;
		reg-names = "qspi-base";
		spi-tx-bus-width = <0x01>;
		spi-rx-bus-width = <0x01>;

		spi-nand@0 {
			compatible = "spi-nand";
			reg = <0x00 0x00 0x00 0x00>;
		};
	};

	voip_ipc@0x2300000 {
		compatible = "cortina,voip_ipc";
		reg = <0x00 0xf4329000 0x00 0x20 0x00 0x80000000 0x00 0x10>;
		memory-region = <0x2e 0x2f>;
		interrupt-parent = <0x0a>;
		interrupts = <0x00>;
		resets = <0x1e 0x12 0x1e 0x14>;
		reset-names = "pe_reset\0rcpu_reset";
	};

	voip_taurus_pe_reset {
		compatible = "rtk,voip_taurus_pe_reset";
		resets = <0x30 0x00 0x30 0x01>;
		reset-names = "pe_reset_cpu0\0pe_reset_cpu1";
	};

	audio_ssp {
		compatible = "realtek,ssp_pinctrl";
		status = "okay";
		pinctrl-0 = <0x31>;
		pinctrl-names = "default";
	};

	fixed_reference {
		#clock-cells = <0x00>;
		compatible = "fixed-clock";
		clock-frequency = <0x17d7840>;
		clock-accuracy = <0x2710>;
		phandle = <0x32>;
	};

	soc_clks {
		compatible = "cortina,rtl8277c-soc-clks";
		reg = <0x00 0xf4320000 0x00 0x1d0>;
		#address-cells = <0x01>;
		#size-cells = <0x00>;

		pll_cpll {
			compatible = "cortina,rtl8277c-pll-cpll-clk";
			#clock-cells = <0x00>;
			clocks = <0x32>;
			phandle = <0x34>;
		};

		pll_fpll {
			compatible = "cortina,rtl8277c-pll-fpll-clk";
			#clock-cells = <0x00>;
			clocks = <0x32>;
			phandle = <0x33>;
		};

		div_f2c {
			compatible = "cortina,div-cpll-clk";
			#clock-cells = <0x00>;
			clocks = <0x33>;
			operate-shift = [07];
			operate-width = [04];
			phandle = <0x35>;
		};

		div_fpll {
			compatible = "cortina,div-fpll-clk";
			#clock-cells = <0x00>;
			clocks = <0x33>;
			operate-shift = [00];
			operate-width = [06];
			phandle = <0x36>;
		};

		div_c2f {
			compatible = "cortina,div-fpll-clk";
			#clock-cells = <0x00>;
			clocks = <0x34>;
			operate-shift = [08];
			operate-width = [06];
			phandle = <0x37>;
		};

		mux_cpu {
			compatible = "cortina,mux-cpu-clk";
			#clock-cells = <0x00>;
			clocks = <0x34 0x35>;
			operate-shift = [0b];
			phandle = <0x38>;
		};

		mux_pe {
			compatible = "cortina,mux-pe-clk";
			#clock-cells = <0x00>;
			clocks = <0x36 0x37>;
			operate-shift = [06];
			phandle = <0x39>;
		};

		div_cortex {
			compatible = "cortina,div-cpll-clk";
			#clock-cells = <0x00>;
			clocks = <0x38>;
			operate-shift = [00];
			operate-width = [06];
			phandle = <0x3c>;
		};

		div_trc {
			compatible = "cortina,div-cpll-clk";
			#clock-cells = <0x00>;
			clocks = <0x38>;
			operate-shift = [0c];
			operate-width = [07];
		};

		div_peaxi {
			compatible = "cortina,div-fpll-clk";
			#clock-cells = <0x00>;
			clocks = <0x39>;
			operate-shift = [10];
			operate-width = [06];
			phandle = <0x3a>;
		};

		mux_peaxi {
			compatible = "cortina,mux-pe-clk";
			#clock-cells = <0x00>;
			clocks = <0x3a 0x39>;
			operate-shift = [16];
		};

		pll_epll {
			compatible = "cortina,rtl8277c-pll-epll-clk";
			#clock-cells = <0x00>;
			clocks = <0x32>;
			phandle = <0x3b>;
		};

		div_crypto {
			compatible = "cortina,div-epll-clk";
			#clock-cells = <0x00>;
			clocks = <0x3b>;
			operate-shift = [00];
			operate-width = [07];
		};

		div_core {
			compatible = "cortina,div-epll-clk";
			#clock-cells = <0x00>;
			clocks = <0x3b>;
			operate-shift = [08];
			operate-width = [07];
		};

		div_cci {
			compatible = "cortina,div-epll2-clk";
			#clock-cells = <0x00>;
			clocks = <0x3b>;
			operate-shift = [08];
			operate-width = [07];
		};

		div_lsaxi {
			compatible = "cortina,div-epll-clk";
			#clock-cells = <0x00>;
			clocks = <0x3b>;
			operate-shift = [18];
			operate-width = [07];
		};

		factor_peripheral {
			compatible = "cortina,fixed-factor-clk";
			#clock-cells = <0x00>;
			clocks = <0x3b>;
			fixed-div = <0x10>;
		};

		factor_usb_suspend {
			compatible = "cortina,fixed-factor-clk";
			#clock-cells = <0x00>;
			clocks = <0x3b>;
			fixed-div = <0xc8>;
		};

		cpu_daemon {
			compatible = "cortina,rtl8277c-cpu-daemon-clk";
			#clock-cells = <0x00>;
			clocks = <0x32 0x34 0x35 0x38 0x3c>;
			phandle = <0x06>;
		};

		gate_pcie0 {
			compatible = "cortina,gate-config-clk";
			#clock-cells = <0x00>;
			operate-shift = [0a];
			phandle = <0x0e>;
		};

		gate_pcie1 {
			compatible = "cortina,gate-config-clk";
			#clock-cells = <0x00>;
			operate-shift = [0c];
			phandle = <0x13>;
		};

		gate_pcie2 {
			compatible = "cortina,gate-config-clk";
			#clock-cells = <0x00>;
			operate-shift = [0e];
			phandle = <0x17>;
		};
	};

	rtk_gpio {
		compatible = "realtek,g3hgu-gpio";
		board-reset-gpio = <0x25 0x08 0x01>;
	};

	gpio-keys {
		compatible = "gpio-keys";
		autorepeat;

		btn_reset {
			label = "btn,reset";
			linux,code = <0x198>;
			gpios = <0x25 0x08 0x01>;
			autorepeat;
		};
	};

	rtk_gpio_led {
		compatible = "realtek,g3hgu-gpio-led";
		#address-cells = <0x01>;
		#size-cells = <0x00>;

		gpio-led0 {
			reg = <0x00>;
			label = "LED_PPP_G";
			led-gpio = <0x25 0x02 0x01>;
			default-state = "off";
		};

		gpio-led1 {
			reg = <0x01>;
			label = "LED_LOS";
			led-gpio = <0x25 0x0a 0x01>;
		};

		gpio-led3 {
			reg = <0x03>;
			label = "LED_PON";
			led-gpio = <0x25 0x09 0x01>;
		};

		gpio-led4 {
			reg = <0x04>;
			label = "LED_PWR_G";
			led-gpio = <0x25 0x0b 0x00>;
		};

		gpio-led5 {
			reg = <0x05>;
			label = "LED_FXS";
			led-gpio = <0x25 0x0c 0x00>;
		};

		gpio-led6 {
			reg = <0x06>;
			label = "LED_EPHY0";
			led-gpio = <0x25 0x04 0x01>;
			linux,default-trigger = "netdev";
		};

		gpio-led7 {
			reg = <0x07>;
			label = "LED_EPHY1";
			led-gpio = <0x25 0x03 0x01>;
			linux,default-trigger = "netdev";
		};

		gpio-led8 {
			reg = <0x08>;
			label = "LED_EPHY2";
			led-gpio = <0x25 0x01 0x01>;
			linux,default-trigger = "netdev";
		};

		gpio-led9 {
			reg = <0x09>;
			label = "LED_EPHY3";
			led-gpio = <0x25 0x00 0x01>;
			linux,default-trigger = "netdev";
		};
	};

	memory {
		device_type = "memory";
		reg = <0x00 0x00 0x00 0x20000000>;
	};

	gpio-reset {
		compatible = "linux,gpio-reset";

		pcie0_device {
			#reset-cells = <0x00>;
			gpios = <0x3d 0x09 0x01>;
			asserted-state = <0x02>;
			duration-ms = <0x96>;
		};
	};
};
